VERSION ""

NS_ :

BS_ :

BU_ : ACU DASH VCU

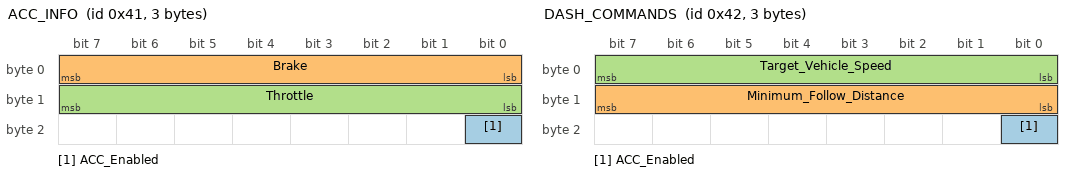
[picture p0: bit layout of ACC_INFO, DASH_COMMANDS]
BO_ 65 ACC_INFO: 3 ACU
  SG_ ACC_Enabled : 16|1@1+ (1,0) [0|1] "" DASH,VCU
  SG_ Brake : 0|8@1+ (1,0) [0|100] "%" DASH,VCU
  SG_ Throttle : 8|8@1+ (1,0) [0|100] "%" DASH,VCU

BO_ 66 DASH_COMMANDS: 3 DASH
  SG_ ACC_Enabled : 16|1@1+ (1,0) [0|1] "" ACU
  SG_ Minimum_Follow_Distance : 8|8@1+ (1,0) [10|150] "ft" ACU
  SG_ Target_Vehicle_Speed : 0|8@1+ (1,0) [0|200] "mph" ACU

BO_ 67 PT_INFO: 3 VCU
  SG_ Lateral_acceleration : 12|12@1+ (1,0) [0|100] "" ACU
  SG_ Vehicle_Speed : 0|12@1+ (1,0) [0|300] "mph" ACU

BA_DEF_ "DBName" STRING;
BA_DEF_ "BusType" STRING;
BA_DEF_ BO_ "VFrameFormat" ENUM "StandardCAN","ExtendedCAN","reserved","J1939PG","reserved","reserved","reserved","reserved","reserved","reserved","reserved","reserved","reserved","reserved","StandardCAN_FD","ExtendedCAN_FD";
BA_DEF_ BO_ "GenMsgSendType" ENUM "Cyclic","Event","CyclicIfActive","SpontanWithDelay","CyclicAndSpontan","CyclicAndSpontanWithDelay";
BA_DEF_ SG_ "GenSigStartValue" FLOAT 0 0;
BA_DEF_DEF_ "DBName" "Cluster";
BA_DEF_DEF_ "BusType" "CAN";
BA_DEF_DEF_ "VFrameFormat" "StandardCAN";
BA_DEF_DEF_ "GenMsgSendType" "Cyclic";
BA_DEF_DEF_ "GenSigStartValue" 0;
BA_ "GenMsgSendType" BO_ 65 1;
BA_ "GenMsgSendType" BO_ 66 1;
BA_ "GenMsgSendType" BO_ 67 1;
BA_ "GenSigStartValue" SG_ 66 Minimum_Follow_Distance 10;
